AUTOSAR XML (schema 4-3-0)
package /Impl_SWC_HALIN_ARPkg
  swc implementation Impl_SWC_HALIN_type: programming-language=C, sw-version=1.0.0, vendor-id=0, behavior=SWC_HALIN_type_IB
    code-descriptors:
      code SRC: artifact-descriptors=autosar-engineering-object={short-label=EngObject, category=SWSRC}
    resource consumption ResourceConsumption
      memory section Mem_SWC_HALIN_CAL: size=0, sw-addrmethod=CAL, symbol=CAL
      memory section Mem_SWC_HALIN_CODE: size=0, sw-addrmethod=CODE, symbol=CODE
package /Impl_Type_HALIN_ARPkg
  8 x impl type:
    BHAL_CAN1_outputs: category=STRUCTURE
      134 x element, all with category=TYPE_REFERENCE:
        VHAL_CANMsgInvalidABM1_flg: implementation-data-type=boolean
        VHAL_ABM1CSErr_flg: implementation-data-type=boolean
        VHAL_ABM1RCErr_flg: implementation-data-type=boolean
        VHAL_ABMPassengerODSSta_flg: implementation-data-type=boolean
        VHAL_ABMRearPassengerCTRODSSta_flg: implementation-data-type=boolean
        VHAL_ABMRearPassengerLHODSSta_flg: implementation-data-type=boolean
        VHAL_ABMRearPassengerRHODSSta_flg: implementation-data-type=boolean
        VHAL_AirBagFailCmd_flg: implementation-data-type=boolean
        VHAL_ChecksumABM1_enum: implementation-data-type=uint8
        VHAL_CrashOutputSts_enum: implementation-data-type=uint8
        VHAL_DriverSeatBeltCmd_flg: implementation-data-type=boolean
        VHAL_LifeCountABM1_enum: implementation-data-type=uint8
        VHAL_PABSwitchCmd_flg: implementation-data-type=boolean
        VHAL_PsngrSeatBeltCmd_flg: implementation-data-type=boolean
        VHAL_RCenterSeatBeltCmd_flg: implementation-data-type=boolean
        VHAL_RDriverSeatBeltCmd_flg: implementation-data-type=boolean
        VHAL_RPsngrSeatBeltCmd_flg: implementation-data-type=boolean
        VHAL_TLHPsngrSeatBeltCmd_flg: implementation-data-type=boolean
        VHAL_TRHPsngrSeatBeltCmd_flg: implementation-data-type=boolean
        VHAL_CANMsgInvalidEPB1_flg: implementation-data-type=boolean
        VHAL_EPB1CSErr_flg: implementation-data-type=boolean
        VHAL_EPB1RCErr_flg: implementation-data-type=boolean
        VHAL_DOASta_flg: implementation-data-type=boolean
        VHAL_EPB1RC_enum: implementation-data-type=uint8
        VHAL_EPBCarWashMode_flg: implementation-data-type=boolean
        VHAL_EPBErrSta_enum: implementation-data-type=uint8
        VHAL_EPBExtApplyAvail_flg: implementation-data-type=boolean
        VHAL_EPBExtReleaseAvail_flg: implementation-data-type=boolean
        VHAL_EPBSta_enum: implementation-data-type=uint8
        VHAL_CANMsgInvalidEPS1_flg: implementation-data-type=boolean
        VHAL_EPS1CSErr_flg: implementation-data-type=boolean
        VHAL_EPS1RCErr_flg: implementation-data-type=boolean
        VHAL_DriIntend_enum: implementation-data-type=uint8
        VHAL_EPSAOIControl_enum: implementation-data-type=uint8
        VHAL_EPSRC_enum: implementation-data-type=uint8
        VHAL_EpasFailed_enum: implementation-data-type=uint8
        VHAL_SASAngle_Deg: implementation-data-type=float32
        VHAL_SASCAL_flg: implementation-data-type=boolean
        VHAL_SASSpeed_degps: implementation-data-type=float32
        VHAL_SASSpeedValid_flg: implementation-data-type=boolean
        VHAL_SASV_flg: implementation-data-type=boolean
        VHAL_CANMsgInvalidESC1_flg: implementation-data-type=boolean
        VHAL_ESC1CSErr_flg: implementation-data-type=boolean
        VHAL_ESC1RCErr_flg: implementation-data-type=boolean
        VHAL_ABSActive_flg: implementation-data-type=boolean
        VHAL_ABSFailed_flg: implementation-data-type=boolean
        VHAL_ABSWnlmpSta_flg: implementation-data-type=boolean
        VHAL_AVHActive_flg: implementation-data-type=boolean
        VHAL_AVHFailed_flg: implementation-data-type=boolean
        VHAL_AmberWnlmpSta_flg: implementation-data-type=boolean
        VHAL_BTCSActive_flg: implementation-data-type=boolean
        VHAL_EBDActive_flg: implementation-data-type=boolean
        VHAL_EBDFailed_flg: implementation-data-type=boolean
        VHAL_ESC1CS_enum: implementation-data-type=uint8
        VHAL_ESC1RC_enum: implementation-data-type=uint8
        VHAL_ESCActive_flg: implementation-data-type=boolean
        VHAL_ESCBeepReq_flg: implementation-data-type=boolean
        VHAL_ESCFailed_flg: implementation-data-type=boolean
        VHAL_ESCOFFStatus_enum: implementation-data-type=uint8
        VHAL_ESCOfflmpSta_flg: implementation-data-type=boolean
        VHAL_ESCWnlmpSta_enum: implementation-data-type=uint8
        VHAL_ESSActive_flg: implementation-data-type=boolean
        VHAL_FrPTCSActive_flg: implementation-data-type=boolean
        VHAL_FrntAxlTrqReqDrv_Nm: implementation-data-type=float32
        VHAL_GRADE_Deg: implementation-data-type=float32
        VHAL_HBBActive_flg: implementation-data-type=boolean
        VHAL_HBBFailed_flg: implementation-data-type=boolean
        VHAL_HDDActive_flg: implementation-data-type=boolean
        VHAL_HDDFailed_flg: implementation-data-type=boolean
        VHAL_HSAActive_flg: implementation-data-type=boolean
        VHAL_HSAFailed_flg: implementation-data-type=boolean
        VHAL_LFPulseCount_enum: implementation-data-type=uint8
        VHAL_LFPulseCountV_flg: implementation-data-type=boolean
        VHAL_LFRawWhlSpeed_kph: implementation-data-type=float32
        VHAL_LFRawWhlSpeedV_flg: implementation-data-type=boolean
        VHAL_LFWhlRotDir_enum: implementation-data-type=uint8
        VHAL_LRPulseCount_enum: implementation-data-type=uint8
        VHAL_LRPulseCountV_flg: implementation-data-type=boolean
        VHAL_LRRawWhlSpeed_kph: implementation-data-type=float32
        VHAL_LRRawWhlSpeedV_flg: implementation-data-type=boolean
        VHAL_LRWhlRotDir_enum: implementation-data-type=uint8
        VHAL_PBAActive_flg: implementation-data-type=boolean
        VHAL_PBAFailed_flg: implementation-data-type=boolean
        VHAL_RFPulseCount_enum: implementation-data-type=uint8
        VHAL_RFPulseCountV_flg: implementation-data-type=boolean
        VHAL_RFRawWhlSpeed_kph: implementation-data-type=float32
        VHAL_RFRawWhlSpeedV_flg: implementation-data-type=boolean
        VHAL_RFWhlRotDir_enum: implementation-data-type=uint8
        VHAL_RRPulseCount_enum: implementation-data-type=uint8
        VHAL_RRPulseCountV_flg: implementation-data-type=boolean
        VHAL_RRRawWhlSpeed_kph: implementation-data-type=float32
        VHAL_RRRawWhlSpeedV_flg: implementation-data-type=boolean
        VHAL_RRWhlRotDir_enum: implementation-data-type=uint8
        VHAL_RearAxlTrqReqDrv_Nm: implementation-data-type=float32
        VHAL_RedWnlmpSta_flg: implementation-data-type=boolean
        VHAL_RrPTCSActive_flg: implementation-data-type=boolean
        VHAL_TCSActive_flg: implementation-data-type=boolean
        VHAL_TCSFailed_flg: implementation-data-type=boolean
        VHAL_VehSpeed_kph: implementation-data-type=float32
        VHAL_CANMsgInvalidESC5_flg: implementation-data-type=boolean
        VHAL_ESC5CSErr_flg: implementation-data-type=boolean
        VHAL_ESC5RCErr_flg: implementation-data-type=boolean
        VHAL_ACCAvail_flg: implementation-data-type=boolean
        VHAL_AEBAvail_flg: implementation-data-type=boolean
        VHAL_ActBrkLampSta_flg: implementation-data-type=boolean
        VHAL_BrkDiscTempSta_flg: implementation-data-type=boolean
        VHAL_BrkPedalPos_pct: implementation-data-type=float32
        VHAL_BrkPedalPosSta_flg: implementation-data-type=boolean
        VHAL_BrkSwSta_flg: implementation-data-type=boolean
        VHAL_BrkSwV_flg: implementation-data-type=boolean
        VHAL_ESC5CS_enum: implementation-data-type=uint8
        VHAL_ESC5RC_enum: implementation-data-type=uint8
        VHAL_ESCADASSta_enum: implementation-data-type=uint8
        VHAL_ESCAPSSta_enum: implementation-data-type=uint8
        VHAL_ESCStandstill_flg: implementation-data-type=boolean
        VHAL_FrRBCActive_flg: implementation-data-type=boolean
        VHAL_FrntAxlTrqReqBrk_Nm: implementation-data-type=float32
        VHAL_LatAccel_Gps: implementation-data-type=float32
        VHAL_LatAccelV_flg: implementation-data-type=boolean
        VHAL_LongAccel_Gps: implementation-data-type=float32
        VHAL_LongAccelV_flg: implementation-data-type=boolean
        VHAL_MCPressure_bar: implementation-data-type=float32
        VHAL_MCPressureV_flg: implementation-data-type=boolean
        VHAL_MeterIndVehSpeed_kph: implementation-data-type=float32
        VHAL_RDCActive_enum: implementation-data-type=uint8
        VHAL_RearAxlTrqReqBrk_Nm: implementation-data-type=float32
        VHAL_RrRBCActive_flg: implementation-data-type=boolean
        VHAL_YawRate_degps: implementation-data-type=float32
        VHAL_YawRateV_flg: implementation-data-type=boolean
        VHAL_CANMsgInvalideBST1_flg: implementation-data-type=boolean
        VHAL_LowBrakeFluidSta_flg: implementation-data-type=boolean
        VHAL_eBSTAmberWnlmpSta_flg: implementation-data-type=boolean
        VHAL_eBSTBeepReq_flg: implementation-data-type=boolean
        VHAL_eBSTRedWnlmpSta_flg: implementation-data-type=boolean
    BHAL_CAN2_outputs: category=STRUCTURE
      196 x element, all with category=TYPE_REFERENCE:
        VHAL_CANMsgInvalidHMI1_flg: implementation-data-type=boolean
        VHAL_HMIACAirIntMCmd_flg: implementation-data-type=boolean
        VHAL_HMIACAirIntPCmd_flg: implementation-data-type=boolean
        VHAL_HMIACAutoBtnCmd_flg: implementation-data-type=boolean
        VHAL_HMIACBtnCmd_flg: implementation-data-type=boolean
        VHAL_HMIACFrDefogBtnCmd_flg: implementation-data-type=boolean
        VHAL_HMIACRecycleBtnCmd_flg: implementation-data-type=boolean
        VHAL_HMIACWindDirMCmd_flg: implementation-data-type=boolean
        VHAL_HMIACWindDirPCmd_flg: implementation-data-type=boolean
        VHAL_HMIAutoInterLightCmd_flg: implementation-data-type=boolean
        VHAL_HMIBCMPostDefogBtnCmd_flg: implementation-data-type=boolean
        VHAL_HMIZLSetTMCmd_flg: implementation-data-type=boolean
        VHAL_HMIZLSetTPCmd_flg: implementation-data-type=boolean
        VHAL_HMIZRSetTMCmd_flg: implementation-data-type=boolean
        VHAL_HMIZRSetTPCmd_flg: implementation-data-type=boolean
        VHAL_CANMsgInvalidIVI1_flg: implementation-data-type=boolean
        VHAL_AmbLighLowBatAlertSW_flg: implementation-data-type=boolean
        VHAL_AmbLighSafetyAlertSW_flg: implementation-data-type=boolean
        VHAL_AmbLightBrightnessSet_enum: implementation-data-type=uint8
        VHAL_AmbLightColorSet_enum: implementation-data-type=uint8
        VHAL_AmbLightDimInDarkSW_flg: implementation-data-type=boolean
        VHAL_AmbLightSW_flg: implementation-data-type=boolean
        VHAL_AmbLightWlcmLightSW_flg: implementation-data-type=boolean
        VHAL_FCPFrEvtBtnACMaxReq_flg: implementation-data-type=boolean
        VHAL_FCPFrEvtBtnACReq_flg: implementation-data-type=boolean
        VHAL_FCPFrEvtBtnAutoReq_flg: implementation-data-type=boolean
        VHAL_FCPFrEvtBtnSyncReq_flg: implementation-data-type=boolean
        VHAL_IVIAutoWipHSpdSWCmd_flg: implementation-data-type=boolean
        VHAL_IVICLWinLockDoorSWSta_flg: implementation-data-type=boolean
        VHAL_IVICreateAccReqSta_enum: implementation-data-type=uint8
        VHAL_IVIDelAccReqSta_enum: implementation-data-type=uint8
        VHAL_IVIDrivingLockSWSta_flg: implementation-data-type=boolean
        VHAL_IVIEPSForceCmd_enum: implementation-data-type=uint8
        VHAL_IVIFrTrunkUnlockReqSta_flg: implementation-data-type=boolean
        VHAL_IVILinkAccReqSta_flg: implementation-data-type=boolean
        VHAL_IVILinkAccSta_enum: implementation-data-type=uint8
        VHAL_IVILinkKeySta_enum: implementation-data-type=uint8
        VHAL_IVILocatedSTA_enum: implementation-data-type=uint8
        VHAL_IVILockSoundSWSta_flg: implementation-data-type=boolean
        VHAL_IVIMirrorFoldedSWSta_flg: implementation-data-type=boolean
        VHAL_IVISWCVibModeSta_enum: implementation-data-type=uint8
        VHAL_IVISilentChrgAlertSta_flg: implementation-data-type=boolean
        VHAL_IVIStoppingUnlockSWSta_flg: implementation-data-type=boolean
        VHAL_IVITimeCheck_enum: implementation-data-type=uint8
        VHAL_IVITimeDay_DAY: implementation-data-type=float32
        VHAL_IVITimeHour_hr: implementation-data-type=float32
        VHAL_IVITimeMinute_min: implementation-data-type=float32
        VHAL_IVITimeMonth_MONTH: implementation-data-type=float32
        VHAL_IVITimeSecond_s: implementation-data-type=float32
        VHAL_IVITimeYear_YEAR: implementation-data-type=float32
        VHAL_IVIWPTCSWSta_flg: implementation-data-type=boolean
        VHAL_IVIsigScreenReqSta_flg: implementation-data-type=boolean
        VHAL_LINKtoDrive_flg: implementation-data-type=boolean
        VHAL_OpenDrOpenWdoSW_flg: implementation-data-type=boolean
        VHAL_PWCONTINUEUSE_flg: implementation-data-type=boolean
        VHAL_SmartEcoModeSW_flg: implementation-data-type=boolean
        VHAL_UserSet_enum: implementation-data-type=uint8
        VHAL_CANMsgInvalidIVI2_flg: implementation-data-type=boolean
        VHAL_ACChgCurSet_A: implementation-data-type=float32
        VHAL_AVMErrSTA_flg: implementation-data-type=boolean
        VHAL_AVMOFFRecButt_flg: implementation-data-type=boolean
        VHAL_AVMParkingmode_enum: implementation-data-type=uint8
        VHAL_AVMparkingcancel_enum: implementation-data-type=uint8
        VHAL_AVMparkingexcute_enum: implementation-data-type=uint8
        VHAL_ApproachUnlockSW_flg: implementation-data-type=boolean
        VHAL_CAASSw_enum: implementation-data-type=uint8
        VHAL_CDLLockButt_flg: implementation-data-type=boolean
        VHAL_CDLUnlockButt_flg: implementation-data-type=boolean
        VHAL_DSEATantiset_flg: implementation-data-type=boolean
        VHAL_DSEATentryfunset_flg: implementation-data-type=boolean
        VHAL_DSEATventreq_enum: implementation-data-type=uint8
        VHAL_Distanceunit_flg: implementation-data-type=boolean
        VHAL_ESCSWCmd_enum: implementation-data-type=uint8
        VHAL_FSOffSw_enum: implementation-data-type=uint8
        VHAL_FollowMeSW_flg: implementation-data-type=boolean
        VHAL_GPSLAT_s: implementation-data-type=float32
        VHAL_GPSLONG_enum: implementation-data-type=uint32
        VHAL_HeadLampSW_enum: implementation-data-type=uint8
        VHAL_HoodLatchSW_enum: implementation-data-type=uint8
        VHAL_IVIACCAdaptiveSta_flg: implementation-data-type=boolean
        VHAL_IVIAirIntZ3Cmd_enum: implementation-data-type=uint8
        VHAL_IVICarWashModeCmd_flg: implementation-data-type=boolean
        VHAL_IVIChargePortSWSta_flg: implementation-data-type=boolean
        VHAL_IVICreepSWReq_flg: implementation-data-type=boolean
        VHAL_IVIDSEATHeaterCmd_enum: implementation-data-type=uint8
        VHAL_IVIDSEATFroEdgeHeightCmd_enum: implementation-data-type=uint8
        VHAL_IVIDSEATHeightCmd_enum: implementation-data-type=uint8
        VHAL_IVIDSEATMemory1Sta_flg: implementation-data-type=boolean
        VHAL_IVIDSEATMemory2Sta_flg: implementation-data-type=boolean
        VHAL_IVIDSEATMemoryOPTCLSSta_flg: implementation-data-type=boolean
        VHAL_IVIDSEATReclineCmd_enum: implementation-data-type=uint8
        VHAL_IVIDSEATSlideCmd_enum: implementation-data-type=uint8
        VHAL_IVIFGSAirIntCmd_enum: implementation-data-type=uint8
        VHAL_IVIFGSChCmd_enum: implementation-data-type=uint8
        VHAL_IVIIONSWCmd_flg: implementation-data-type=boolean
        VHAL_IVIISAOffsetSpd_enum: implementation-data-type=uint8
        VHAL_IVINightModeSta_flg: implementation-data-type=boolean
        VHAL_IVIPSEATHeaterCmd_enum: implementation-data-type=uint8
        VHAL_IVIPSEATReclineCmd_enum: implementation-data-type=uint8
        VHAL_IVIPSEATSlideCmd_enum: implementation-data-type=uint8
        VHAL_IVIPTGModeSW_enum: implementation-data-type=uint8
        VHAL_IVIPTGOpenHeight_enum: implementation-data-type=uint8
        VHAL_IVIPTGStaSW_enum: implementation-data-type=uint8
        VHAL_IVIPTGUSStaSW_flg: implementation-data-type=boolean
        VHAL_IVIPWModeReq_enum: implementation-data-type=uint8
        VHAL_IVIPwrLockSW_enum: implementation-data-type=uint8
        VHAL_IVIPwroffreq_flg: implementation-data-type=boolean
        VHAL_IVIRRDefReq_flg: implementation-data-type=boolean
        VHAL_IVIReqV2L_enum: implementation-data-type=uint8
        VHAL_IVISWCRUndefinedSta_enum: implementation-data-type=uint8
        VHAL_IVIScreen_enum: implementation-data-type=uint8
        VHAL_IVIStartChgreq_flg: implementation-data-type=boolean
        VHAL_IVIStatus_flg: implementation-data-type=boolean
        VHAL_IVIStopChgreq_flg: implementation-data-type=boolean
        VHAL_IVITrailerCheckReqSta_flg: implementation-data-type=boolean
        VHAL_IVITrailerModeSWSta_flg: implementation-data-type=boolean
        VHAL_IVITriggerreq_flg: implementation-data-type=boolean
        VHAL_IVIUnlockChgreq_flg: implementation-data-type=boolean
        VHAL_IVIWIMAINSW_flg: implementation-data-type=boolean
        VHAL_LDrvControlCommand_pct: implementation-data-type=float32
        VHAL_LPasControlCommand_pct: implementation-data-type=float32
        VHAL_LRLDControlCommand_pct: implementation-data-type=float32
        VHAL_LRRDControlCommand_pct: implementation-data-type=float32
        VHAL_LightShowStartReq_flg: implementation-data-type=boolean
        VHAL_LightShowStopReq_flg: implementation-data-type=boolean
        VHAL_MFRDNBrightReq_pct: implementation-data-type=float32
        VHAL_OFFACMODE_enum: implementation-data-type=uint8
        VHAL_PSEATventreq_enum: implementation-data-type=uint8
        VHAL_PerdV2L_enum: implementation-data-type=uint8
        VHAL_RFogLampSW_flg: implementation-data-type=boolean
        VHAL_RollModeSWCmd_enum: implementation-data-type=uint8
        VHAL_RoomLampMode_flg: implementation-data-type=boolean
        VHAL_SOCADJBUTT_flg: implementation-data-type=boolean
        VHAL_SOCLimitSet_pct: implementation-data-type=float32
        VHAL_SOCV2LLimit_pct: implementation-data-type=float32
        VHAL_SchedChgStart_flg: implementation-data-type=boolean
        VHAL_SchedChgStop_flg: implementation-data-type=boolean
        VHAL_SchedChgbutt_flg: implementation-data-type=boolean
        VHAL_SchedChglimit_pct: implementation-data-type=float32
        VHAL_SchedChgwake_flg: implementation-data-type=boolean
        VHAL_SenstivityPosition_enum: implementation-data-type=uint8
        VHAL_SetUnlockSingle_flg: implementation-data-type=boolean
        VHAL_TCSSWCmd_enum: implementation-data-type=uint8
        VHAL_TPMSCaliButt_flg: implementation-data-type=boolean
        VHAL_TPMSResButt_flg: implementation-data-type=boolean
        VHAL_TurnSwTimeSet_enum: implementation-data-type=uint8
        VHAL_WalkawayLockSW_flg: implementation-data-type=boolean
        VHAL_WlcmLightMode_enum: implementation-data-type=uint8
        VHAL_sigAirIntenZon1Req_enum: implementation-data-type=uint8
        VHAL_sigDfrstReq_flg: implementation-data-type=boolean
        VHAL_sigFaceReq_flg: implementation-data-type=boolean
        VHAL_sigFootReq_flg: implementation-data-type=boolean
        VHAL_sigRecircReq_flg: implementation-data-type=boolean
        VHAL_sigSetTempZon1Req_C: implementation-data-type=float32
        VHAL_sigSetTempZon2Req_C: implementation-data-type=float32
        VHAL_CANMsgInvalidIVI3_flg: implementation-data-type=boolean
        VHAL_IVICLBlowerYSta_pct: implementation-data-type=float32
        VHAL_IVICLBlowerZSta_pct: implementation-data-type=float32
        VHAL_IVICRBlowerYSta_pct: implementation-data-type=float32
        VHAL_IVICRBlowerZSta_pct: implementation-data-type=float32
        VHAL_IVIHMICustmiFunSta_enum: implementation-data-type=uint8
        VHAL_IVIHMICustmiKEYSta_enum: implementation-data-type=uint8
        VHAL_IVILBlowerModeSta_enum: implementation-data-type=uint8
        VHAL_IVILBlowerYSta_pct: implementation-data-type=float32
        VHAL_IVILBlowerZSta_pct: implementation-data-type=float32
        VHAL_IVILSEATventCmd_enum: implementation-data-type=uint8
        VHAL_IVIMLFMostCmd_flg: implementation-data-type=boolean
        VHAL_IVIMLFootLiftCmd_enum: implementation-data-type=uint8
        VHAL_IVIMLNapModeCmd_flg: implementation-data-type=boolean
        VHAL_IVIMLReclinerCmd_enum: implementation-data-type=uint8
        VHAL_IVIMLRestoreCmd_flg: implementation-data-type=boolean
        VHAL_IVIMLSEATventCmd_enum: implementation-data-type=uint8
        VHAL_IVIMLSeatLiftCmd_enum: implementation-data-type=uint8
        VHAL_IVIMLSldRestoreCmd_flg: implementation-data-type=boolean
        VHAL_IVIMLSliderCmd_enum: implementation-data-type=uint8
        VHAL_IVIMLZeroGravityCmd_flg: implementation-data-type=boolean
        VHAL_IVIMRFMostCmd_flg: implementation-data-type=boolean
        VHAL_IVIMRFootLiftCmd_enum: implementation-data-type=uint8
        VHAL_IVIMRNapModeCmd_flg: implementation-data-type=boolean
        VHAL_IVIMRReclinerCmd_enum: implementation-data-type=uint8
        VHAL_IVIMRRestoreCmd_flg: implementation-data-type=boolean
        VHAL_IVIMRSEATventCmd_enum: implementation-data-type=uint8
        VHAL_IVIMRSeatLiftCmd_enum: implementation-data-type=uint8
        VHAL_IVIMRSldRestoreCmd_flg: implementation-data-type=boolean
        VHAL_IVIMRSliderCmd_enum: implementation-data-type=uint8
        VHAL_IVIMRZeroGravityCmd_flg: implementation-data-type=boolean
        VHAL_IVIRBlowerModeSta_enum: implementation-data-type=uint8
        VHAL_IVIRBlowerYSta_pct: implementation-data-type=float32
        VHAL_IVIRBlowerZSta_pct: implementation-data-type=float32
        VHAL_IVIRSEATventCmd_enum: implementation-data-type=uint8
        VHAL_IVISnowModeCmd_flg: implementation-data-type=boolean
        VHAL_IVIUserTakeOverAPSSta_flg: implementation-data-type=boolean
        VHAL_IVIZon1WindDirSWReqSta_flg: implementation-data-type=boolean
        VHAL_CANMsgInvalidMETER1_flg: implementation-data-type=boolean
        VHAL_METERKPHCalcu_kph: implementation-data-type=float32
        VHAL_ODOMETER_km: implementation-data-type=float32
    BHAL_CAN3_outputs: category=STRUCTURE
      298 x element, all with category=TYPE_REFERENCE:
        VHAL_CANMsgInvalidBMS1_flg: implementation-data-type=boolean
        VHAL_BMS1CSErr_flg: implementation-data-type=boolean
        VHAL_BMS1RCErr_flg: implementation-data-type=boolean
        VHAL_BMSChckSum1_enum: implementation-data-type=uint8
        VHAL_BMSRolCnct1_enum: implementation-data-type=uint8
        VHAL_HVBPwrAvailChrg_kW: implementation-data-type=float32
        VHAL_HVBPwrAvailChrg30_kW: implementation-data-type=float32
        VHAL_HVBPwrAvailChrg60_kW: implementation-data-type=float32
        VHAL_HVBPwrAvailDchrg_kW: implementation-data-type=float32
        VHAL_HVBPwrAvailDchrg30_kW: implementation-data-type=float32
        VHAL_HVBPwrAvailDchrg60_kW: implementation-data-type=float32
        VHAL_HVBattCurr_A: implementation-data-type=float32
        VHAL_HVBattVolt_V: implementation-data-type=float32
        VHAL_CANMsgInvalidBMS3_flg: implementation-data-type=boolean
        VHAL_ACChrgCurrDis_A: implementation-data-type=float32
        VHAL_FireDetErr_flg: implementation-data-type=boolean
        VHAL_HVBChrgPwr_kWh: implementation-data-type=float32
        VHAL_HVBChrgPwrTotal_kWh: implementation-data-type=float32
        VHAL_HVBDrvPwr_kWh: implementation-data-type=float32
        VHAL_HVBDrvPwrTotal_kWh: implementation-data-type=float32
        VHAL_HVBFullChrgPwr_kWh: implementation-data-type=float32
        VHAL_HVBIsoImpedenceN_Megaohm: implementation-data-type=float32
        VHAL_HVBIsoImpedenceP_Megaohm: implementation-data-type=float32
        VHAL_HVBSOH_pct: implementation-data-type=float32
        VHAL_HVBattErr_flg: implementation-data-type=boolean
        VHAL_HVBattPackVolt_V: implementation-data-type=float32
        VHAL_HVBattSOC_pct: implementation-data-type=float32
        VHAL_HVBattSOCDis_pct: implementation-data-type=float32
        VHAL_RemainChrgTime_min: implementation-data-type=float32
        VHAL_CANMsgInvalidBMS4_flg: implementation-data-type=boolean
        VHAL_CellTempAvg_C: implementation-data-type=float32
        VHAL_HVBCellVoltMax_mV: implementation-data-type=float32
        VHAL_HVBCellVoltMin_mV: implementation-data-type=float32
        VHAL_HVBMTempMax_C: implementation-data-type=float32
        VHAL_HVBMTempMin_C: implementation-data-type=float32
        VHAL_MaxCellTempNum_enum: implementation-data-type=uint8
        VHAL_MaxCellVoltNum_enum: implementation-data-type=uint8
        VHAL_MinCellTempNum_enum: implementation-data-type=uint8
        VHAL_MinCellVoltNum_enum: implementation-data-type=uint8
        VHAL_CANMsgInvalidBMS5_flg: implementation-data-type=boolean
        VHAL_HVInVolt_V: implementation-data-type=float32
        VHAL_LVBattDet12V_V: implementation-data-type=float32
        VHAL_OBCACCSLimit_A: implementation-data-type=float32
        VHAL_OBCDCCurLm_A: implementation-data-type=float32
        VHAL_OBCDCVoltLm_V: implementation-data-type=float32
        VHAL_CANMsgInvalidBMS6_flg: implementation-data-type=boolean
        VHAL_BMS6CSErr_flg: implementation-data-type=boolean
        VHAL_BMS6RCErr_flg: implementation-data-type=boolean
        VHAL_BMSChckSum_enum: implementation-data-type=uint8
        VHAL_BMSRolCnct_enum: implementation-data-type=uint8
        VHAL_BMSREADY_flg: implementation-data-type=boolean
        VHAL_BMSWarn{1..8}_flg: implementation-data-type=boolean
        VHAL_ChrgInLockReq_enum: implementation-data-type=uint8
        VHAL_ChrgPlugSta_enum: implementation-data-type=uint8
        VHAL_DisChrgPlugErr_enum: implementation-data-type=uint8
        VHAL_ExtChrgSta_enum: implementation-data-type=uint8
        VHAL_HVBChrgErr_enum: implementation-data-type=uint8
        VHAL_HVBContactorSta_flg: implementation-data-type=boolean
        VHAL_HVBHVILErr_flg: implementation-data-type=boolean
        VHAL_HVBOvrTempErr_flg: implementation-data-type=boolean
        VHAL_HVBOvrTempWarn_enum: implementation-data-type=uint8
        VHAL_HVBPreheatPrecoolSta_enum: implementation-data-type=uint8
        VHAL_HVBattReady4Pre_enum: implementation-data-type=uint8
        VHAL_HVILSta_flg: implementation-data-type=boolean
        VHAL_V2LSta_enum: implementation-data-type=uint8
        VHAL_CANMsgInvalidBMS8_flg: implementation-data-type=boolean
        VHAL_MainRlyNegSta_enum: implementation-data-type=uint8
        VHAL_MainRlyPosSta_enum: implementation-data-type=uint8
        VHAL_CANMsgInvalidCCU1_flg: implementation-data-type=boolean
        VHAL_CCU1CSErr_flg: implementation-data-type=boolean
        VHAL_CCU1RCErr_flg: implementation-data-type=boolean
        VHAL_CSCCU1_enum: implementation-data-type=uint8
        VHAL_DCDCAuxCur_A: implementation-data-type=float32
        VHAL_DCDCAuxVolt_V: implementation-data-type=float32
        VHAL_DCDCHVCur_A: implementation-data-type=float32
        VHAL_DCDCInVoltInf_V: implementation-data-type=float32
        VHAL_DCDCPreCompleted_enum: implementation-data-type=uint8
        VHAL_OBCDCCurrInf_A: implementation-data-type=float32
        VHAL_OBCDCVoltInf_V: implementation-data-type=float32
        VHAL_OBCPreCompleted_enum: implementation-data-type=uint8
        VHAL_OBCWakeup4Plugin_flg: implementation-data-type=boolean
        VHAL_RCCCU1_enum: implementation-data-type=uint8
        VHAL_CANMsgInvalidCCU2_flg: implementation-data-type=boolean
        VHAL_CCU2CSErr_flg: implementation-data-type=boolean
        VHAL_CCU2RCErr_flg: implementation-data-type=boolean
        VHAL_CSCCU2_enum: implementation-data-type=uint8
        VHAL_DCDCEnaSta_flg: implementation-data-type=boolean
        VHAL_DCDCFaultSta_enum: implementation-data-type=uint8
        VHAL_DCDCReady4Pre_flg: implementation-data-type=boolean
        VHAL_DCDCTemp_C: implementation-data-type=float32
        VHAL_OBCACCurrInf_A: implementation-data-type=float32
        VHAL_OBCACVoltInf_V: implementation-data-type=float32
        VHAL_OBCEnaSta_flg: implementation-data-type=boolean
        VHAL_OBCFaultSta_enum: implementation-data-type=uint8
        VHAL_OBCPluginSta_flg: implementation-data-type=boolean
        VHAL_OBCReady4Pre_flg: implementation-data-type=boolean
        VHAL_OBCTemp_C: implementation-data-type=float32
        VHAL_OBCV2LSta_enum: implementation-data-type=uint8
        VHAL_OBCACCurLim_enum: implementation-data-type=uint8
        VHAL_RCCCU2_enum: implementation-data-type=uint8
        VHAL_CANMsgInvalidEBM1_flg: implementation-data-type=boolean
        VHAL_EBMErrSta_enum: implementation-data-type=uint8
        VHAL_EBMRLampSta_enum: implementation-data-type=uint8
        VHAL_CANMsgInvalidMCUBF1_flg: implementation-data-type=boolean
        VHAL_MCUBF1CSErr_flg: implementation-data-type=boolean
        VHAL_MCUBF1RCErr_flg: implementation-data-type=boolean
        VHAL_FrActvDmpDisabSta_flg: implementation-data-type=boolean
        VHAL_FrEDUDrtSta_flg: implementation-data-type=boolean
        VHAL_FrEDUOpratingSta_flg: implementation-data-type=boolean
        VHAL_FrEDURealTMTq_Nm: implementation-data-type=float32
        VHAL_FrEDURotateDirction_enum: implementation-data-type=uint8
        VHAL_FrEDUTqReqFbk_Nm: implementation-data-type=float32
        VHAL_FrMCU1Chksum_enum: implementation-data-type=uint8
        VHAL_FrMCU1RolCnt_enum: implementation-data-type=uint8
        VHAL_FrMCUBAT_V: implementation-data-type=float32
        VHAL_FrMCUDCBusCurr_A: implementation-data-type=float32
        VHAL_FrMCUDCBusVolt_V: implementation-data-type=float32
        VHAL_FrMCUDischrgSta_flg: implementation-data-type=boolean
        VHAL_FrMCUEnaSta_flg: implementation-data-type=boolean
        VHAL_FrMCUErr_enum: implementation-data-type=uint8
        VHAL_FrMCUIGNsta_flg: implementation-data-type=boolean
        VHAL_FrMCUReady_flg: implementation-data-type=boolean
        VHAL_FrMCUReady4Pre_flg: implementation-data-type=boolean
        VHAL_FrMCUSysSta_enum: implementation-data-type=uint8
        VHAL_FrMCUTemp_C: implementation-data-type=float32
        VHAL_FrMotorAvailTq_Nm: implementation-data-type=float32
        VHAL_FrRegenAvailTq_Nm: implementation-data-type=float32
        VHAL_FrTMSpd_rpm: implementation-data-type=float32
        VHAL_FrTMTemp_C: implementation-data-type=float32
        VHAL_FrTMid_A: implementation-data-type=float32
        VHAL_FrTMiq_A: implementation-data-type=float32
        VHAL_MCUWarnF_enum: implementation-data-type=uint8
        VHAL_MCUBFRealPwrKwSta_kW: implementation-data-type=float32
        VHAL_CANMsgInvalidMCUBF2_flg: implementation-data-type=boolean
        VHAL_FrCoolanttempReq_C: implementation-data-type=float32
        VHAL_FrFailcode1_enum: implementation-data-type=uint8
        VHAL_FrFailcode2_enum: implementation-data-type=uint8
        VHAL_FrFailcodehistory1_enum: implementation-data-type=uint8
        VHAL_FrFailcodehistory2_enum: implementation-data-type=uint8
        VHAL_FrLLCTemp_C: implementation-data-type=float32
        VHAL_FrLLCflowReq_Lpmin: implementation-data-type=float32
        VHAL_FrMCUTempWarn_enum: implementation-data-type=uint8
        VHAL_FrMCUHWVer_enum: implementation-data-type=uint16
        VHAL_FrMCUSWVer_enum: implementation-data-type=uint16
        VHAL_FrTMTempWarn_enum: implementation-data-type=uint8
        VHAL_MCUBFLLCTempWarnSta_enum: implementation-data-type=uint8
        VHAL_CANMsgInvalidMCUBR1_flg: implementation-data-type=boolean
        VHAL_MCUBR1CSErr_flg: implementation-data-type=boolean
        VHAL_MCUBR1RCErr_flg: implementation-data-type=boolean
        VHAL_MCUWarnR_enum: implementation-data-type=uint8
        VHAL_MCUBRRealPwrKwSta_kW: implementation-data-type=float32
        VHAL_RrActvDmpDisabSta_flg: implementation-data-type=boolean
        VHAL_RrEDUDrtSta_flg: implementation-data-type=boolean
        VHAL_RrEDUOpratingSta_flg: implementation-data-type=boolean
        VHAL_RrEDURealTMTq_Nm: implementation-data-type=float32
        VHAL_RrEDURotateDirction_enum: implementation-data-type=uint8
        VHAL_RrEDUTqReqFbk_Nm: implementation-data-type=float32
        VHAL_RrMCU1Chksum_enum: implementation-data-type=uint8
        VHAL_RrMCU1RolCnt_enum: implementation-data-type=uint8
        VHAL_RrMCUBAT_V: implementation-data-type=float32
        VHAL_RrMCUDCBusCurr_A: implementation-data-type=float32
        VHAL_RrMCUDCBusVolt_V: implementation-data-type=float32
        VHAL_RrMCUDischrgSta_flg: implementation-data-type=boolean
        VHAL_RrMCUEnaSta_flg: implementation-data-type=boolean
        VHAL_RrMCUErr_enum: implementation-data-type=uint8
        VHAL_RrMCUIGNsta_flg: implementation-data-type=boolean
        VHAL_RrMCUReady_flg: implementation-data-type=boolean
        VHAL_RrMCUReady4Pre_flg: implementation-data-type=boolean
        VHAL_RrMCUSysSta_enum: implementation-data-type=uint8
        VHAL_RrMCUTemp_C: implementation-data-type=float32
        VHAL_RrMotorAvailTq_Nm: implementation-data-type=float32
        VHAL_RrRegenAvailTq_Nm: implementation-data-type=float32
        VHAL_RrTMSpd_rpm: implementation-data-type=float32
        VHAL_RrTMTemp_C: implementation-data-type=float32
        VHAL_RrTMid_A: implementation-data-type=float32
        VHAL_RrTMiq_A: implementation-data-type=float32
        VHAL_CANMsgInvalidMCUBR2_flg: implementation-data-type=boolean
        VHAL_MCUBRLLCTempWarnSta_enum: implementation-data-type=uint8
        VHAL_RrCoolanttempReq_cnt: implementation-data-type=float32
        VHAL_RrFailcode1_enum: implementation-data-type=uint8
        VHAL_RrFailcode2_enum: implementation-data-type=uint8
        VHAL_RrFailcodehistory1_enum: implementation-data-type=uint8
        VHAL_RrFailcodehistory2_enum: implementation-data-type=uint8
        VHAL_RrLLCTemp_C: implementation-data-type=float32
        VHAL_RrLLCflowReq_Lpmin: implementation-data-type=float32
        VHAL_RrMCU3HWVer_enum: implementation-data-type=uint16
        VHAL_RrMCU3SWVer_enum: implementation-data-type=uint16
        VHAL_RrMCUTempWarn_enum: implementation-data-type=uint8
        VHAL_RrTMTempWarn_enum: implementation-data-type=uint8
        VHAL_CANMsgInvalidMCUNF1_flg: implementation-data-type=boolean
        VHAL_MCUNF1CSErr_flg: implementation-data-type=boolean
        VHAL_MCUNF1RCErr_flg: implementation-data-type=boolean
        VHAL_FrActvDmpDisabStaNidec_flg: implementation-data-type=boolean
        VHAL_FrEDUDrtStaNidec_flg: implementation-data-type=boolean
        VHAL_FrEDUOpratingStaNidec_flg: implementation-data-type=boolean
        VHAL_FrEDURealTMTqNidec_Nm: implementation-data-type=float32
        VHAL_FrEDURotateDirctionNidec_enum: implementation-data-type=uint8
        VHAL_FrEDUTqReqFbkNidec_Nm: implementation-data-type=float32
        VHAL_FrMCU1ChksumNidec_enum: implementation-data-type=uint8
        VHAL_FrMCU1RolCntNidec_enum: implementation-data-type=uint8
        VHAL_FrMCUBATNidec_V: implementation-data-type=float32
        VHAL_FrMCUDCBusCurrNidec_A: implementation-data-type=float32
        VHAL_FrMCUDCBusVoltNidec_V: implementation-data-type=float32
        VHAL_FrMCUDischrgStaNidec_flg: implementation-data-type=boolean
        VHAL_FrMCUEnaStaNidec_flg: implementation-data-type=boolean
        VHAL_FrMCUErrNidec_enum: implementation-data-type=uint8
        VHAL_FrMCUIGNstaNidec_flg: implementation-data-type=boolean
        VHAL_FrMCUReady4PreNidec_flg: implementation-data-type=boolean
        VHAL_FrMCUReadyNidec_flg: implementation-data-type=boolean
        VHAL_FrMCUSysStaNidec_enum: implementation-data-type=uint8
        VHAL_FrMCUTempNidec_C: implementation-data-type=float32
        VHAL_FrMotorAvailTqNidec_Nm: implementation-data-type=float32
        VHAL_FrRegenAvailTqNidec_Nm: implementation-data-type=float32
        VHAL_FrTMSpdNidec_rpm: implementation-data-type=float32
        VHAL_FrTMTempNidec_C: implementation-data-type=float32
        VHAL_FrTMidNidec_A: implementation-data-type=float32
        VHAL_FrTMiqNidec_A: implementation-data-type=float32
        VHAL_MCUWarnFNidec_enum: implementation-data-type=uint8
        VHAL_CANMsgInvalidMCUNF2_flg: implementation-data-type=boolean
        VHAL_FrCoolanttempReqNidec_C: implementation-data-type=float32
        VHAL_FrEOPSpdSetNidec_rpm: implementation-data-type=float32
        VHAL_FrFailcode1Nidec_enum: implementation-data-type=uint8
        VHAL_FrFailcode2Nidec_enum: implementation-data-type=uint8
        VHAL_FrFailcodehistory1Nidec_enum: implementation-data-type=uint8
        VHAL_FrFailcodehistory2Nidec_enum: implementation-data-type=uint8
        VHAL_FrLLCTempNidec_C: implementation-data-type=float32
        VHAL_FrLLCflowReqNidec_Lpmin: implementation-data-type=float32
        VHAL_FrMCUTempWarnNidec_enum: implementation-data-type=uint8
        VHAL_FrTMTempWarnNidec_enum: implementation-data-type=uint8
        VHAL_CANMsgInvalidMCUNF3_flg: implementation-data-type=boolean
        VHAL_FrMCUHWVerNidec_enum: implementation-data-type=uint16
        VHAL_FrMCUSWVerNidec_enum: implementation-data-type=uint16
        VHAL_CANMsgInvalidMCUNR1_flg: implementation-data-type=boolean
        VHAL_MCUNR1CSErr_flg: implementation-data-type=boolean
        VHAL_MCUNR1RCErr_flg: implementation-data-type=boolean
        VHAL_MCUWarnRNidec_enum: implementation-data-type=uint8
        VHAL_RrActvDmpDisabStaNidec_flg: implementation-data-type=boolean
        VHAL_RrEDUDrtStaNidec_flg: implementation-data-type=boolean
        VHAL_RrEDUOpratingStaNidec_flg: implementation-data-type=boolean
        VHAL_RrEDURealTMTqNidec_Nm: implementation-data-type=float32
        VHAL_RrEDURotateDirctionNidec_enum: implementation-data-type=uint8
        VHAL_RrEDUTqReqFbkNidec_Nm: implementation-data-type=float32
        VHAL_RrMCU1ChksumNidec_enum: implementation-data-type=uint8
        VHAL_RrMCU1RolCntNidec_enum: implementation-data-type=uint8
        VHAL_RrMCUBATNidec_V: implementation-data-type=float32
        VHAL_RrMCUDCBusCurrNidec_A: implementation-data-type=float32
        VHAL_RrMCUDCBusVoltNidec_V: implementation-data-type=float32
        VHAL_RrMCUDischrgStaNidec_flg: implementation-data-type=boolean
        VHAL_RrMCUEnaStaNidec_flg: implementation-data-type=boolean
        VHAL_RrMCUErrNidec_enum: implementation-data-type=uint8
        VHAL_RrMCUIGNstaNidec_flg: implementation-data-type=boolean
        VHAL_RrMCUReady4PreNidec_flg: implementation-data-type=boolean
        VHAL_RrMCUReadyNidec_flg: implementation-data-type=boolean
        VHAL_RrMCUSysStaNidec_enum: implementation-data-type=uint8
        VHAL_RrMCUTempNidec_C: implementation-data-type=float32
        VHAL_RrMotorAvailTqNidec_Nm: implementation-data-type=float32
        VHAL_RrRegenAvailTqNidec_Nm: implementation-data-type=float32
        VHAL_RrTMSpdNidec_rpm: implementation-data-type=float32
        VHAL_RrTMTempNidec_C: implementation-data-type=float32
        VHAL_RrTMidNidec_A: implementation-data-type=float32
        VHAL_RrTMiqNidec_A: implementation-data-type=float32
        VHAL_CANMsgInvalidMCUNR2_flg: implementation-data-type=boolean
        VHAL_RrCoolanttempReqNidec_cnt: implementation-data-type=float32
        VHAL_RrEOPSpdSetNidec_rpm: implementation-data-type=float32
        VHAL_RrFailcode1Nidec_enum: implementation-data-type=uint8
        VHAL_RrFailcode2Nidec_enum: implementation-data-type=uint8
        VHAL_RrFailcodehistory1Nidec_enum: implementation-data-type=uint8
        VHAL_RrFailcodehistory2Nidec_enum: implementation-data-type=uint8
        VHAL_RrLLCTempNidec_C: implementation-data-type=float32
        VHAL_RrLLCflowReqNidec_Lpmin: implementation-data-type=float32
        VHAL_RrMCUTempWarnNidec_enum: implementation-data-type=uint8
        VHAL_RrTMTempWarnNidec_enum: implementation-data-type=uint8
        VHAL_CANMsgInvalidMCUNR3_flg: implementation-data-type=boolean
        VHAL_RrMCU3HWVerNidec_enum: implementation-data-type=uint16
        VHAL_RrMCU3SWVerNidec_enum: implementation-data-type=uint16
        VHAL_CANMsgInvalidShifter1_flg: implementation-data-type=boolean
        VHAL_Shifter1CSErr_flg: implementation-data-type=boolean
        VHAL_Shifter1RCErr_flg: implementation-data-type=boolean
        VHAL_ShifterCRC8_enum: implementation-data-type=uint8
        VHAL_ShifterFailsta_enum: implementation-data-type=uint8
        VHAL_ShifterHandleCmd_enum: implementation-data-type=uint8
        VHAL_ShifterRC_enum: implementation-data-type=uint8
        VHAL_CANMsgInvalidShifter2_flg: implementation-data-type=boolean
        VHAL_Shifter2CSErr_flg: implementation-data-type=boolean
        VHAL_Shifter2RCErr_flg: implementation-data-type=boolean
        VHAL_CSW2DimSwSta_flg: implementation-data-type=boolean
        VHAL_CSW2FWasSwSta_enum: implementation-data-type=uint8
        VHAL_CSW2FWipSwSta_enum: implementation-data-type=uint8
        VHAL_CSW2PassSWSta_flg: implementation-data-type=boolean
        VHAL_CSW2RWipWasSwSta_enum: implementation-data-type=uint8
        VHAL_CSW2TurnSwSta_enum: implementation-data-type=uint8
    BHAL_CAN4_outputs: category=STRUCTURE
      272 x element, all with category=TYPE_REFERENCE:
        VHAL_CANMsgInvalidBodyZoneDR1_flg: implementation-data-type=boolean
        VHAL_BDDSEATAntiSta_flg: implementation-data-type=boolean
        VHAL_BDDSEATEntryFunSta_flg: implementation-data-type=boolean
        VHAL_BDDSEATErrorSta_flg: implementation-data-type=boolean
        VHAL_BDDSEATMemSetSta_enum: implementation-data-type=uint8
        VHAL_BDDSEATModeSta_enum: implementation-data-type=uint8
        VHAL_BDDSEATVentSta_enum: implementation-data-type=uint8
        VHAL_BDDSEATheaterSta_enum: implementation-data-type=uint8
        VHAL_CANMsgInvalidBodyZoneDR2_flg: implementation-data-type=boolean
        VHAL_BDAPMWinFOpenedSta_pct: implementation-data-type=float32
        VHAL_BDAPMWinROpenedSta_pct: implementation-data-type=float32
        VHAL_BDDoorFHandleCloseSta_flg: implementation-data-type=boolean
        VHAL_BDDoorRHandleCloseSta_flg: implementation-data-type=boolean
        VHAL_CANMsgInvalidBodyZonePS1_flg: implementation-data-type=boolean
        VHAL_BPPSEATErrorSta_flg: implementation-data-type=boolean
        VHAL_BPPSEATModeSta_enum: implementation-data-type=uint8
        VHAL_BPPSEATVentSta_enum: implementation-data-type=uint8
        VHAL_BPPSEATheaterSta_enum: implementation-data-type=uint8
        VHAL_BPPTGActiveSta_enum: implementation-data-type=uint8
        VHAL_BPPTGExistSta_flg: implementation-data-type=boolean
        VHAL_BPPTGInsideSW1Sta_enum: implementation-data-type=uint8
        VHAL_BPPTGInsideSW2Sta_enum: implementation-data-type=uint8
        VHAL_BPPTGIsSetHeightSta_flg: implementation-data-type=boolean
        VHAL_BPPTGLeftHallPosnSta_enum: implementation-data-type=uint16
        VHAL_BPPTGOpenRatioSta_pct: implementation-data-type=float32
        VHAL_BPPTGRDILCmd_enum: implementation-data-type=uint8
        VHAL_BPPTGSysSta_enum: implementation-data-type=uint8
        VHAL_CANMsgInvalidBodyZonePS2_flg: implementation-data-type=boolean
        VHAL_BPAPMWinFOpenedSta_pct: implementation-data-type=float32
        VHAL_BPAPMWinROpenedSta_pct: implementation-data-type=float32
        VHAL_BPDoorFHandleCloseSta_flg: implementation-data-type=boolean
        VHAL_BPDoorRHandleCloseSta_flg: implementation-data-type=boolean
        VHAL_BPSEATLVentSta_enum: implementation-data-type=uint8
        VHAL_BPSEATMLVentSta_enum: implementation-data-type=uint8
        VHAL_BPSEATMRVentSta_enum: implementation-data-type=uint8
        VHAL_BPSEATRVentSta_enum: implementation-data-type=uint8
        VHAL_CANMsgInvalidDKC1_flg: implementation-data-type=boolean
        VHAL_DKCKeyNumSta_enum: implementation-data-type=uint8
        VHAL_DKCKeyTypeSta_enum: implementation-data-type=uint8
        VHAL_DKCPDkeyAreaRAPSSta_enum: implementation-data-type=uint8
        VHAL_DKCParkingModeCmd_enum: implementation-data-type=uint8
        VHAL_DKCReVehData_enum: implementation-data-type=uint8
        VHAL_PCommandToBCM_enum: implementation-data-type=uint8
        VHAL_PCommandToPTG_enum: implementation-data-type=uint8
        VHAL_PDKeyAreaLockUnlock_enum: implementation-data-type=uint8
        VHAL_PDKeyAreaPS_enum: implementation-data-type=uint8
        VHAL_PDKeyAreaPTG_enum: implementation-data-type=uint8
        VHAL_PDKeyWelcome_enum: implementation-data-type=uint8
        VHAL_PDkeyShowIVI_enum: implementation-data-type=uint8
        VHAL_PKeyMiss_flg: implementation-data-type=boolean
        VHAL_PKeyMode_enum: implementation-data-type=uint8
        VHAL_PUIDLowPower_flg: implementation-data-type=boolean
        VHAL_CANMsgInvalidDKC2_flg: implementation-data-type=boolean
        VHAL_EncryptionDATA063_enum: implementation-data-type=uint64
        VHAL_EncryptionDATA64127_enum: implementation-data-type=uint64
        VHAL_RandomNumberX_enum: implementation-data-type=uint64
        VHAL_CANMsgInvalidPTG1_flg: implementation-data-type=boolean
        VHAL_PTGActiveSta_enum: implementation-data-type=uint8
        VHAL_PTGAutoStaus_flg: implementation-data-type=boolean
        VHAL_PTGExist_flg: implementation-data-type=boolean
        VHAL_PTGHWVer_enum: implementation-data-type=uint8
        VHAL_PTGInnerSW2_enum: implementation-data-type=uint8
        VHAL_PTGIsSetHeight_flg: implementation-data-type=boolean
        VHAL_PTGOpenRatio_pct: implementation-data-type=float32
        VHAL_PTGRDILSta_enum: implementation-data-type=uint8
        VHAL_PTGSWVer_enum: implementation-data-type=uint8
        VHAL_PTGSysSta_enum: implementation-data-type=uint8
        VHAL_CANMsgInvalidZONEDR1_flg: implementation-data-type=boolean
        VHAL_DrLockSta_flg: implementation-data-type=boolean
        VHAL_MIRRORFOLDSW_flg: implementation-data-type=boolean
        VHAL_RLTurnLPErr_flg: implementation-data-type=boolean
        VHAL_RLTurnLampC_mA: implementation-data-type=float32
        VHAL_RRTurnLPErr_flg: implementation-data-type=boolean
        VHAL_RRTurnLampC_mA: implementation-data-type=float32
        VHAL_RWiperAS_flg: implementation-data-type=boolean
        VHAL_RWiperProtection_flg: implementation-data-type=boolean
        VHAL_CANMsgInvalidZONEDRVCU_flg: implementation-data-type=boolean
        VHAL_BlowerErr_enum: implementation-data-type=uint8
        VHAL_DrPMMLVOutPErrLmp_flg: implementation-data-type=boolean
        VHAL_DrPMMSysErrLmp_flg: implementation-data-type=boolean
        VHAL_DrSCPSysErrLmp_flg: implementation-data-type=boolean
        VHAL_DrStdAErrSta_flg: implementation-data-type=boolean
        VHAL_LeftHallPos_enum: implementation-data-type=uint16
        VHAL_SolarL_W: implementation-data-type=float32
        VHAL_SolarLErr_enum: implementation-data-type=uint8
        VHAL_SolarR_W: implementation-data-type=float32
        VHAL_SolarRErr_enum: implementation-data-type=uint8
        VHAL_TFaceL_C: implementation-data-type=float32
        VHAL_TFaceLErr_enum: implementation-data-type=uint8
        VHAL_TFaceR_C: implementation-data-type=float32
        VHAL_TFaceRErr_enum: implementation-data-type=uint8
        VHAL_TFaceRr_C: implementation-data-type=float32
        VHAL_TFaceRrErr_enum: implementation-data-type=uint8
        VHAL_TFootL_C: implementation-data-type=float32
        VHAL_TFootLErr_enum: implementation-data-type=uint8
        VHAL_TFootR_C: implementation-data-type=float32
        VHAL_TFootRErr_enum: implementation-data-type=uint8
        VHAL_TFootRr_C: implementation-data-type=float32
        VHAL_TFootRrErr_enum: implementation-data-type=uint8
        VHAL_Tevap_C: implementation-data-type=float32
        VHAL_TevapErr_enum: implementation-data-type=uint8
        VHAL_Tincar_C: implementation-data-type=float32
        VHAL_TincarErr_enum: implementation-data-type=uint8
        VHAL_ZoneDrMalfunLevel_enum: implementation-data-type=uint8
        VHAL_CANMsgInvalidZONEFR1_flg: implementation-data-type=boolean
        VHAL_ChargeInletLockSta_flg: implementation-data-type=boolean
        VHAL_CompProEN_flg: implementation-data-type=boolean
        VHAL_FLTurnLPErr_flg: implementation-data-type=boolean
        VHAL_FLTurnLampC_mA: implementation-data-type=float32
        VHAL_FLTurnLightWarning_flg: implementation-data-type=boolean
        VHAL_FRTurnLPErr_flg: implementation-data-type=boolean
        VHAL_FRTurnLampC_mA: implementation-data-type=float32
        VHAL_FRTurnLightWarning_flg: implementation-data-type=boolean
        VHAL_FWiperAS_flg: implementation-data-type=boolean
        VHAL_FWiperProtection_flg: implementation-data-type=boolean
        VHAL_LADBHibeamIndication_flg: implementation-data-type=boolean
        VHAL_LADBOperationStatus_flg: implementation-data-type=boolean
        VHAL_LADBWarning_flg: implementation-data-type=boolean
        VHAL_LAHBWarning_flg: implementation-data-type=boolean
        VHAL_LDRLWarning_flg: implementation-data-type=boolean
        VHAL_LLBWarning_flg: implementation-data-type=boolean
        VHAL_LpositionLampWarning_flg: implementation-data-type=boolean
        VHAL_RADBHibeamIndication_flg: implementation-data-type=boolean
        VHAL_RADBOperationStatus_flg: implementation-data-type=boolean
        VHAL_RADBWarning_flg: implementation-data-type=boolean
        VHAL_RAHBWarning_flg: implementation-data-type=boolean
        VHAL_RDRLWarning_flg: implementation-data-type=boolean
        VHAL_RLBWarning_flg: implementation-data-type=boolean
        VHAL_RpositionLampWarning_flg: implementation-data-type=boolean
        VHAL_TrailerCheck_flg: implementation-data-type=boolean
        VHAL_TrailerModeSta_enum: implementation-data-type=uint8
        VHAL_ZFRBCMChargerDoorSWSta_flg: implementation-data-type=boolean
        VHAL_ZFRBCMHRLTurnLPNormalSta_flg: implementation-data-type=boolean
        VHAL_ZFRBCMHRRTurnLPHNormalSta_flg: implementation-data-type=boolean
        VHAL_ZFRTHCMCLEVentActYSta_pct: implementation-data-type=float32
        VHAL_ZFRTHCMCREVentActYSta_pct: implementation-data-type=float32
        VHAL_ZFRTHCMLEVentActYSta_pct: implementation-data-type=float32
        VHAL_ZFRTHCMREVentActYSta_pct: implementation-data-type=float32
        VHAL_CANMsgInvalidZONEFRVCU_flg: implementation-data-type=boolean
        VHAL_AGSErr_enum: implementation-data-type=uint8
        VHAL_BatInTemp_C: implementation-data-type=float32
        VHAL_BatInTempErr_enum: implementation-data-type=uint8
        VHAL_BatOutTemp_C: implementation-data-type=float32
        VHAL_COMPErr_enum: implementation-data-type=uint8
        VHAL_EACProtectEnable_enum: implementation-data-type=uint8
        VHAL_EWP3Err_enum: implementation-data-type=uint8
        VHAL_EXV1Err_enum: implementation-data-type=uint8
        VHAL_EXV2Err_enum: implementation-data-type=uint8
        VHAL_FanErr_enum: implementation-data-type=uint8
        VHAL_FrPMMLimpHomeActReq_flg: implementation-data-type=boolean
        VHAL_MotorInTemp_C: implementation-data-type=float32
        VHAL_MotorInTempErr_enum: implementation-data-type=uint8
        VHAL_MotorOutTemp_C: implementation-data-type=float32
        VHAL_MotorOutTempErr_enum: implementation-data-type=uint8
        VHAL_PTHighP_KPa: implementation-data-type=float32
        VHAL_PTHighPErr_enum: implementation-data-type=uint8
        VHAL_PTHighTact_C: implementation-data-type=float32
        VHAL_PTHighTactErr_enum: implementation-data-type=uint8
        VHAL_PTLowP1_KPa: implementation-data-type=float32
        VHAL_PTLowP1Err_enum: implementation-data-type=uint8
        VHAL_PTLowP2_KPa: implementation-data-type=float32
        VHAL_PTLowP2Err_enum: implementation-data-type=uint8
        VHAL_PTLowT1_C: implementation-data-type=float32
        VHAL_PTLowT1Err_enum: implementation-data-type=uint8
        VHAL_PTLowT2_C: implementation-data-type=float32
        VHAL_PTLowT2Err_enum: implementation-data-type=uint8
        VHAL_SOTXVErr_enum: implementation-data-type=uint8
        VHAL_SOV{1..3}Err_enum: implementation-data-type=uint8
        VHAL_Tamb_C: implementation-data-type=float32
        VHAL_TambErr_enum: implementation-data-type=uint8
        VHAL_CANMsgInvalidzGWAPTC1_flg: implementation-data-type=boolean
        VHAL_FrntPTCLeActHeatPwr_W: implementation-data-type=float32
        VHAL_FrntPTCRearLeActHeatPwr_W: implementation-data-type=float32
        VHAL_FrntPTCRearRiActHeatPwr_W: implementation-data-type=float32
        VHAL_FrntPTCRiActHeatPwr_W: implementation-data-type=float32
        VHAL_CANMsgInvalidzGWCANFr1_flg: implementation-data-type=boolean
        VHAL_COMPActualPwr_W: implementation-data-type=float32
        VHAL_COMPConCur_A: implementation-data-type=float32
        VHAL_COMPConVolt_V: implementation-data-type=float32
        VHAL_COMPStatorSpd_rpm: implementation-data-type=float32
        VHAL_PTC1PowerConsumption_kW: implementation-data-type=float32
        VHAL_CANMsgInvalidzGWLINDr1_flg: implementation-data-type=boolean
        VHAL_CSWDimSw_flg: implementation-data-type=boolean
        VHAL_CSWFWasSwSta_enum: implementation-data-type=uint8
        VHAL_CSWFWipSwSta_enum: implementation-data-type=uint8
        VHAL_CSWPassSWSta_flg: implementation-data-type=boolean
        VHAL_CSWRWasSWSta_enum: implementation-data-type=uint8
        VHAL_CSWRWipIntSwSta_enum: implementation-data-type=uint8
        VHAL_CSWTurnSwSta_enum: implementation-data-type=uint8
        VHAL_FAPWL01LINResponseError_flg: implementation-data-type=boolean
        VHAL_LDrvMotorRelayError_flg: implementation-data-type=boolean
        VHAL_LDrvMotorRippleError_flg: implementation-data-type=boolean
        VHAL_LDrvValWdwOpened_pct: implementation-data-type=float32
        VHAL_LDrvWdwPositionSts_enum: implementation-data-type=uint8
        VHAL_LPasMotorRelayError_flg: implementation-data-type=boolean
        VHAL_LPasMotorRippleError_flg: implementation-data-type=boolean
        VHAL_LPasValWdwOpened_pct: implementation-data-type=float32
        VHAL_LPasWdwPositionSts_enum: implementation-data-type=uint8
        VHAL_LRLDMotorRelayError_flg: implementation-data-type=boolean
        VHAL_LRLDMotorRippleError_flg: implementation-data-type=boolean
        VHAL_LRLDValWdwOpened_pct: implementation-data-type=float32
        VHAL_LRLDWdwPositionSts_enum: implementation-data-type=uint8
        VHAL_LRRDMotorRelayError_flg: implementation-data-type=boolean
        VHAL_LRRDMotorRippleError_flg: implementation-data-type=boolean
        VHAL_LRRDValWdwOpened_pct: implementation-data-type=float32
        VHAL_LRRDWdwPositionSts_enum: implementation-data-type=uint8
        VHAL_RAPWL01LINResponseError_flg: implementation-data-type=boolean
        VHAL_RLSLampSta_flg: implementation-data-type=boolean
        VHAL_RLSRainSnrWiperCmd_enum: implementation-data-type=uint8
        VHAL_SWC2LADASSta_flg: implementation-data-type=boolean
        VHAL_SWC2LDriveModeSta_flg: implementation-data-type=boolean
        VHAL_SWC2LHomeSta_flg: implementation-data-type=boolean
        VHAL_SWC2LLeftSta_flg: implementation-data-type=boolean
        VHAL_SWC2LRegenUpSta_flg: implementation-data-type=boolean
        VHAL_SWC2LRightSta_flg: implementation-data-type=boolean
        VHAL_SWC2LScrollDownSta_flg: implementation-data-type=boolean
        VHAL_SWC2LScrollPressSta_flg: implementation-data-type=boolean
        VHAL_SWC2LScrollUpSta_flg: implementation-data-type=boolean
        VHAL_SWC2RCustomizeSta_flg: implementation-data-type=boolean
        VHAL_SWC2RLeftSta_flg: implementation-data-type=boolean
        VHAL_SWC2RPageSwitchSta_flg: implementation-data-type=boolean
        VHAL_SWC2RRegenDownSta_flg: implementation-data-type=boolean
        VHAL_SWC2RRightSta_flg: implementation-data-type=boolean
        VHAL_SWC2RScrollDownSta_flg: implementation-data-type=boolean
        VHAL_SWC2RScrollPressSta_flg: implementation-data-type=boolean
        VHAL_SWC2RScrollUpSta_flg: implementation-data-type=boolean
        VHAL_SWC2RVRSta_flg: implementation-data-type=boolean
        VHAL_SWCACCSta_flg: implementation-data-type=boolean
        VHAL_SWCCANCELSta_flg: implementation-data-type=boolean
        VHAL_SWCDistanceSta_flg: implementation-data-type=boolean
        VHAL_SWCDownSta_flg: implementation-data-type=boolean
        VHAL_SWCLKASta_flg: implementation-data-type=boolean
        VHAL_SWCLeftSta_flg: implementation-data-type=boolean
        VHAL_SWCRegenDown_flg: implementation-data-type=boolean
        VHAL_SWCRegenUp_flg: implementation-data-type=boolean
        VHAL_SWCResUpSta_flg: implementation-data-type=boolean
        VHAL_SWCRightSta_flg: implementation-data-type=boolean
        VHAL_SWCSetdownSta_flg: implementation-data-type=boolean
        VHAL_SWCTripSta_flg: implementation-data-type=boolean
        VHAL_SWCUndefinedSta_flg: implementation-data-type=boolean
        VHAL_SWCUpSta_flg: implementation-data-type=boolean
        VHAL_SWCVRSta_flg: implementation-data-type=boolean
        VHAL_SWCmodeSta_flg: implementation-data-type=boolean
        VHAL_CANMsgInvalidzGWLINDr2_flg: implementation-data-type=boolean
        VHAL_ACT1ResponseError_flg: implementation-data-type=boolean
        VHAL_CANMsgInvalidzGWLINFr1_flg: implementation-data-type=boolean
        VHAL_AGSActualPosition_enum: implementation-data-type=uint8
        VHAL_FGSIntenRspSta_enum: implementation-data-type=uint8
        VHAL_CANMsgInvalidzGWLINFr2_flg: implementation-data-type=boolean
        VHAL_EWP1BlockError_enum: implementation-data-type=uint8
        VHAL_EWP1OverCurrError_enum: implementation-data-type=uint8
        VHAL_EWP2BlockError_enum: implementation-data-type=uint8
        VHAL_EWP2OverCurrError_enum: implementation-data-type=uint8
        VHAL_EWP3BlockError_enum: implementation-data-type=uint8
        VHAL_EWP3OverCurrError_enum: implementation-data-type=uint8
        VHAL_CANMsgInvalidzGWSEAT1_flg: implementation-data-type=boolean
        VHAL_DSEATAntiSta_flg: implementation-data-type=boolean
        VHAL_DSEATEntryFunSta_flg: implementation-data-type=boolean
        VHAL_DSEATErrorSta_flg: implementation-data-type=boolean
        VHAL_DSEATHWVer_enum: implementation-data-type=uint16
        VHAL_DSEATMode_enum: implementation-data-type=uint8
        VHAL_DSEATSWVer_enum: implementation-data-type=uint16
        VHAL_DSEATVentSta_enum: implementation-data-type=uint8
        VHAL_DSEATheatersta_enum: implementation-data-type=uint8
        VHAL_PSEATErrorSta_flg: implementation-data-type=boolean
        VHAL_PSEATHWVer_enum: implementation-data-type=uint16
        VHAL_PSEATMode_enum: implementation-data-type=uint8
        VHAL_PSEATSWVer_enum: implementation-data-type=uint16
        VHAL_PSEATVentSta_enum: implementation-data-type=uint8
        VHAL_PSEATheatersta_enum: implementation-data-type=uint8
    BHAL_CAN5_outputs: category=STRUCTURE
      21 x element, all with category=TYPE_REFERENCE:
        VHAL_CANMsgInvalidTBOX2_flg: implementation-data-type=boolean
        VHAL_TimeSyncFromBSDay_DAY: implementation-data-type=float32
        VHAL_TimeSyncFromBSHour_hr: implementation-data-type=float32
        VHAL_TimeSyncFromBSMinute_min: implementation-data-type=float32
        VHAL_TimeSyncFromBSMonth_MONTH: implementation-data-type=float32
        VHAL_TimeSyncFromBSSecond_s: implementation-data-type=float32
        VHAL_TimeSyncFromBSYear_YEAR: implementation-data-type=float32
        VHAL_CANMsgInvalidTBOX3_flg: implementation-data-type=boolean
        VHAL_ChargePercentSet_pct: implementation-data-type=float32
        VHAL_ReserveChargeOFFDay_DAY: implementation-data-type=float32
        VHAL_ReserveChargeOFFHour_hr: implementation-data-type=float32
        VHAL_ReserveChargeOFFMinute_min: implementation-data-type=float32
        VHAL_ReserveChargeOFFMonth_MONTH: implementation-data-type=float32
        VHAL_ReserveChargeOFFYear_YEAR: implementation-data-type=float32
        VHAL_ReserveChargeOnDay_DAY: implementation-data-type=float32
        VHAL_ReserveChargeOnHour_hr: implementation-data-type=float32
        VHAL_ReserveChargeOnMinute_min: implementation-data-type=float32
        VHAL_ReserveChargeOnMonth_MONTH: implementation-data-type=float32
        VHAL_ReserveChargeOnYear_YEAR: implementation-data-type=float32
        VHAL_TBOXHWVER_enum: implementation-data-type=uint32
        VHAL_TBOXSWVER_enum: implementation-data-type=uint32
    BHAL_CAN6_outputs: category=STRUCTURE
      99 x element, all with category=TYPE_REFERENCE:
        VHAL_CANMsgInvalidFCM1_flg: implementation-data-type=boolean
        VHAL_ACCComfortBandLower_mps2: implementation-data-type=float32
        VHAL_ACCComfortBandUpper_mps2: implementation-data-type=float32
        VHAL_ACCJerkLowerLimit_mps3: implementation-data-type=float32
        VHAL_ACCJerkUpperLimit_mps3: implementation-data-type=float32
        VHAL_ACCObjDist_m: implementation-data-type=float32
        VHAL_ACCObjDstLvl_enum: implementation-data-type=uint8
        VHAL_ACCObjRelSpd_mps: implementation-data-type=float32
        VHAL_ACCRequiredAccel_mps2: implementation-data-type=float32
        VHAL_ACCTakeoverReq_flg: implementation-data-type=boolean
        VHAL_ACCVehHoldReq_flg: implementation-data-type=boolean
        VHAL_ADASACCSta_enum: implementation-data-type=uint8
        VHAL_ADASAEBReq_enum: implementation-data-type=uint8
        VHAL_ADASAEBSta_enum: implementation-data-type=uint8
        VHAL_ADASCAMSpdLim_enum: implementation-data-type=uint8
        VHAL_ADASDBSReq_enum: implementation-data-type=uint8
        VHAL_ADASFCWMute_flg: implementation-data-type=boolean
        VHAL_ADASFCWSta_enum: implementation-data-type=uint8
        VHAL_ADASFaultSta_flg: implementation-data-type=boolean
        VHAL_ADASFltWrnReq_flg: implementation-data-type=boolean
        VHAL_ADASForceIdle_flg: implementation-data-type=boolean
        VHAL_ADASISASta_enum: implementation-data-type=uint8
        VHAL_ADASLDWMute_flg: implementation-data-type=boolean
        VHAL_ADASLDWSta_enum: implementation-data-type=uint8
        VHAL_ADASLFCHandsOffWarning_enum: implementation-data-type=uint8
        VHAL_ADASLFCSta_enum: implementation-data-type=uint8
        VHAL_ADASLFCWarnSound_enum: implementation-data-type=uint8
        VHAL_ADASLKASta_enum: implementation-data-type=uint8
        VHAL_ADASLaneModeL_enum: implementation-data-type=uint8
        VHAL_ADASLaneModeR_enum: implementation-data-type=uint8
        VHAL_ADASLanecurveL_raw32: implementation-data-type=float32
        VHAL_ADASLanecurveR_raw32: implementation-data-type=float32
        VHAL_ADASLanetypeL_enum: implementation-data-type=uint8
        VHAL_ADASLanetypeR_enum: implementation-data-type=uint8
        VHAL_ADASSLIFSpdLim_enum: implementation-data-type=uint8
        VHAL_ADASSLIFSta_enum: implementation-data-type=uint8
        VHAL_ADASShftPosnReq_enum: implementation-data-type=uint8
        VHAL_ADASShftPosnReqA_flg: implementation-data-type=boolean
        VHAL_ADASVehSpdLim_enum: implementation-data-type=uint8
        VHAL_ADASWarningMsg_enum: implementation-data-type=uint8
        VHAL_AEBVehHoldReq_flg: implementation-data-type=boolean
        VHAL_CameraBlockage_flg: implementation-data-type=boolean
        VHAL_FCM1Checksum_enum: implementation-data-type=uint8
        VHAL_FCM1LifeCount_enum: implementation-data-type=uint8
        VHAL_FCMACCmode_enum: implementation-data-type=uint8
        VHAL_FCMLKAStrToqReq_Nm: implementation-data-type=float32
        VHAL_FCMLKATOIAct_enum: implementation-data-type=uint8
        VHAL_FCMLKATOIFault_flg: implementation-data-type=boolean
        VHAL_ForceLowBeam_enum: implementation-data-type=uint8
        VHAL_HazardWarningReq_flg: implementation-data-type=boolean
        VHAL_ISAWarningMsg_enum: implementation-data-type=uint8
        VHAL_LKAHODDisplayWarning_flg: implementation-data-type=boolean
        VHAL_LKAHODSoundWarning_flg: implementation-data-type=boolean
        VHAL_LVDAACCStatusInformation_flg: implementation-data-type=boolean
        VHAL_LVDADisabled_flg: implementation-data-type=boolean
        VHAL_LVDAFailinfo_flg: implementation-data-type=boolean
        VHAL_LVDAMuteSta_enum: implementation-data-type=uint8
        VHAL_LVDAWarning_flg: implementation-data-type=boolean
        VHAL_LeftTurnLightReq_flg: implementation-data-type=boolean
        VHAL_RightTurnLightReq_flg: implementation-data-type=boolean
        VHAL_TargetType_enum: implementation-data-type=uint8
        VHAL_TimeGapLevel_enum: implementation-data-type=uint8
        VHAL_CANMsgInvalidFCM2_flg: implementation-data-type=boolean
        VHAL_FCM2CSErr_flg: implementation-data-type=boolean
        VHAL_FCM2RCErr_flg: implementation-data-type=boolean
        VHAL_ADBVehDst1Val_enum: implementation-data-type=uint8
        VHAL_CANMsgInvalidFCM3_flg: implementation-data-type=boolean
        VHAL_MELaneCurvDervLt_raw32: implementation-data-type=float32
        VHAL_MELaneCurvDervLt2_raw32: implementation-data-type=float32
        VHAL_MELaneCurvDervRt_raw32: implementation-data-type=float32
        VHAL_MELaneCurvDervRt2_raw32: implementation-data-type=float32
        VHAL_MELaneCurvLt_raw32: implementation-data-type=float32
        VHAL_MELaneCurvLt2_raw32: implementation-data-type=float32
        VHAL_MELaneCurvRt_raw32: implementation-data-type=float32
        VHAL_MELaneCurvRt2_raw32: implementation-data-type=float32
        VHAL_MELaneHeadAngLt_radians: implementation-data-type=float32
        VHAL_MELaneHeadAngLt2_radians: implementation-data-type=float32
        VHAL_MELaneHeadAngRt_radians: implementation-data-type=float32
        VHAL_MELaneHeadAngRt2_radians: implementation-data-type=float32
        VHAL_MELanePosLt_m: implementation-data-type=float32
        VHAL_MELanePosLt2_m: implementation-data-type=float32
        VHAL_MELanePosRt_m: implementation-data-type=float32
        VHAL_MELanePosRt2_m: implementation-data-type=float32
        VHAL_CANMsgInvalidFCM4_flg: implementation-data-type=boolean
        VHAL_FCM4CSErr_flg: implementation-data-type=boolean
        VHAL_FCM4RCErr_flg: implementation-data-type=boolean
        VHAL_ADASAngCtrlTqWeightGain_pct: implementation-data-type=float32
        VHAL_ADASDesStrWhlAngCtrlCmd_Deg: implementation-data-type=float32
        VHAL_ADASDrvInputTqBoostAct_flg: implementation-data-type=boolean
        VHAL_ADASDrvInputTqBoostGain_pct: implementation-data-type=float32
        VHAL_ADASMaxAngCtrlOutTqLimit_Nm: implementation-data-type=float32
        VHAL_ADASStrWhlAngCtrlStatus_flg: implementation-data-type=boolean
        VHAL_CANMsgInvalidSRR1_flg: implementation-data-type=boolean
        VHAL_SRRBSDWarnL_enum: implementation-data-type=uint8
        VHAL_SRRBSDWarnR_enum: implementation-data-type=uint8
        VHAL_SRRODASoundL_flg: implementation-data-type=boolean
        VHAL_SRRODASoundR_flg: implementation-data-type=boolean
        VHAL_SRRODAWarnL_enum: implementation-data-type=uint8
        VHAL_SRRODAWarnR_enum: implementation-data-type=uint8
    u8_Array16_type: category=ARRAY
      element u8_Array16: category=VALUE, array-size=16, array-size-semantics=FIXED-SIZE, base-type=uint8
    u8_Array8_type: category=ARRAY
      element u8_Array8: category=VALUE, array-size=8, array-size-semantics=FIXED-SIZE, base-type=uint8
package /Interface_HALIN_ARPkg
  6 x sender receiver interface:
    IF_BHAL_CAN1_outputs
      data BHAL_CAN1_outputs: type=BHAL_CAN1_outputs
    IF_BHAL_CAN2_outputs
      data BHAL_CAN2_outputs: type=BHAL_CAN2_outputs
    IF_BHAL_CAN3_outputs
      data BHAL_CAN3_outputs: type=BHAL_CAN3_outputs
    IF_BHAL_CAN4_outputs
      data BHAL_CAN4_outputs: type=BHAL_CAN4_outputs
    IF_BHAL_CAN5_outputs
      data BHAL_CAN5_outputs: type=BHAL_CAN5_outputs
    IF_BHAL_CAN6_outputs
      data BHAL_CAN6_outputs: type=BHAL_CAN6_outputs
package /SWC_HALIN_ARPkg
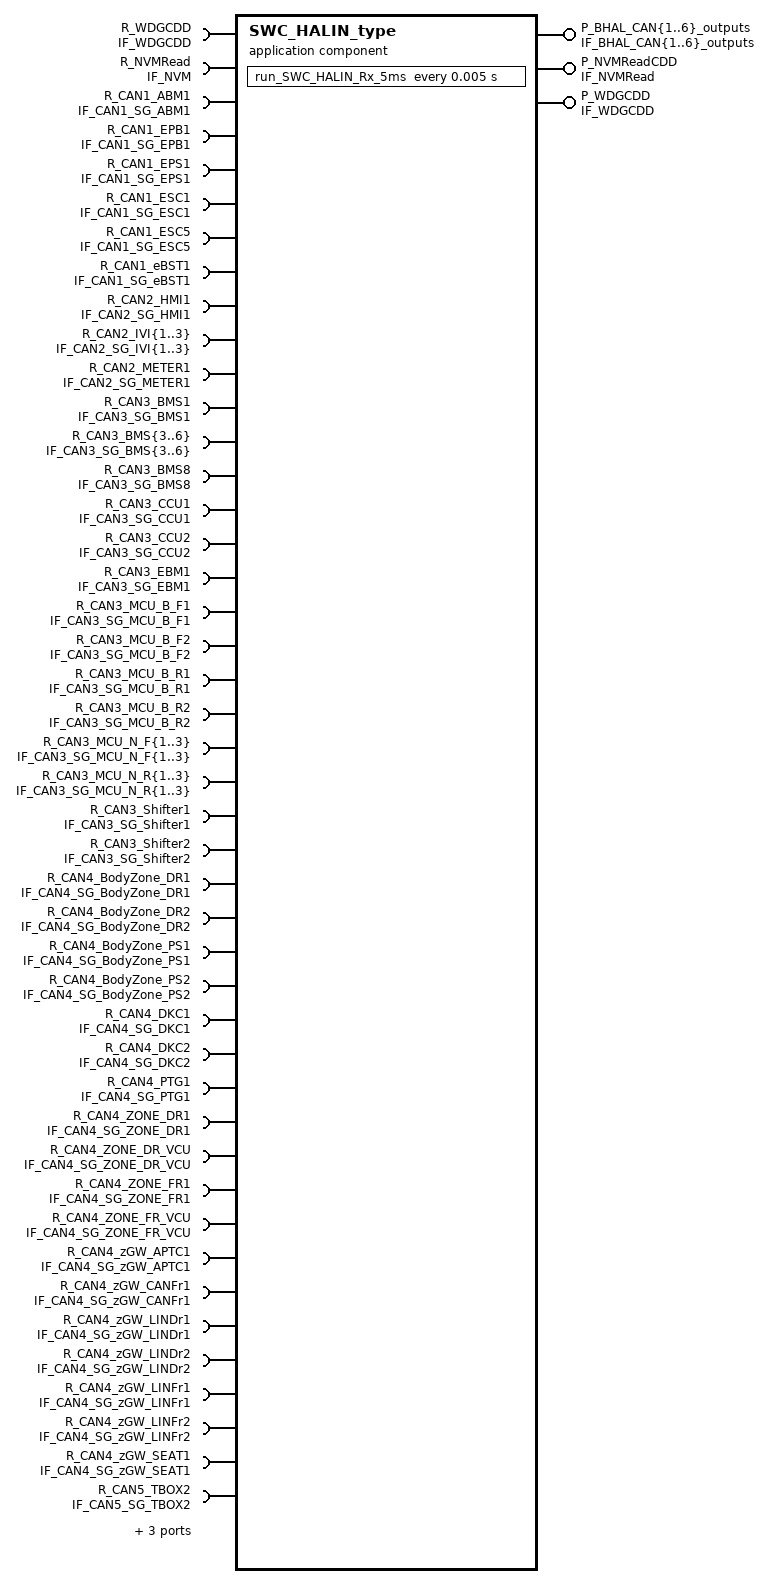
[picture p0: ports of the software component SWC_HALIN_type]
  application sw component type SWC_HALIN_type
    8 x provide port:
      P_BHAL_CAN{1..6}_outputs: provided-interface=IF_BHAL_CAN{1..6}_outputs
      P_NVMReadCDD: provided-interface=IF_NVMRead
      P_WDGCDD: provided-interface=IF_WDGCDD
    59 x require port:
      R_WDGCDD: required-interface=IF_WDGCDD
      R_NVMRead: nv-require-com-spec{init-value=1024 x 0, variable=NV_FVTDataArray}, required-interface=IF_NVM
      R_CAN1_ABM1: required-interface=IF_CAN1_SG_ABM1
      R_CAN1_EPB1: required-interface=IF_CAN1_SG_EPB1
      R_CAN1_EPS1: required-interface=IF_CAN1_SG_EPS1
      R_CAN1_ESC1: required-interface=IF_CAN1_SG_ESC1
      R_CAN1_ESC5: required-interface=IF_CAN1_SG_ESC5
      R_CAN1_eBST1: required-interface=IF_CAN1_SG_eBST1
      R_CAN2_HMI1: required-interface=IF_CAN2_SG_HMI1
      R_CAN2_IVI{1..3}: required-interface=IF_CAN2_SG_IVI{1..3}
      R_CAN2_METER1: required-interface=IF_CAN2_SG_METER1
      R_CAN3_BMS1: required-interface=IF_CAN3_SG_BMS1
      R_CAN3_BMS{3..6}: required-interface=IF_CAN3_SG_BMS{3..6}
      R_CAN3_BMS8: required-interface=IF_CAN3_SG_BMS8
      R_CAN3_CCU1: required-interface=IF_CAN3_SG_CCU1
      R_CAN3_CCU2: required-interface=IF_CAN3_SG_CCU2
      R_CAN3_EBM1: required-interface=IF_CAN3_SG_EBM1
      R_CAN3_MCU_B_F1: required-interface=IF_CAN3_SG_MCU_B_F1
      R_CAN3_MCU_B_F2: required-interface=IF_CAN3_SG_MCU_B_F2
      R_CAN3_MCU_B_R1: required-interface=IF_CAN3_SG_MCU_B_R1
      R_CAN3_MCU_B_R2: required-interface=IF_CAN3_SG_MCU_B_R2
      R_CAN3_MCU_N_F{1..3}: required-interface=IF_CAN3_SG_MCU_N_F{1..3}
      R_CAN3_MCU_N_R{1..3}: required-interface=IF_CAN3_SG_MCU_N_R{1..3}
      R_CAN3_Shifter1: required-interface=IF_CAN3_SG_Shifter1
      R_CAN3_Shifter2: required-interface=IF_CAN3_SG_Shifter2
      R_CAN4_BodyZone_DR1: required-interface=IF_CAN4_SG_BodyZone_DR1
      R_CAN4_BodyZone_DR2: required-interface=IF_CAN4_SG_BodyZone_DR2
      R_CAN4_BodyZone_PS1: required-interface=IF_CAN4_SG_BodyZone_PS1
      R_CAN4_BodyZone_PS2: required-interface=IF_CAN4_SG_BodyZone_PS2
      R_CAN4_DKC1: required-interface=IF_CAN4_SG_DKC1
      R_CAN4_DKC2: required-interface=IF_CAN4_SG_DKC2
      R_CAN4_PTG1: required-interface=IF_CAN4_SG_PTG1
      R_CAN4_ZONE_DR1: required-interface=IF_CAN4_SG_ZONE_DR1
      R_CAN4_ZONE_DR_VCU: required-interface=IF_CAN4_SG_ZONE_DR_VCU
      R_CAN4_ZONE_FR1: required-interface=IF_CAN4_SG_ZONE_FR1
      R_CAN4_ZONE_FR_VCU: required-interface=IF_CAN4_SG_ZONE_FR_VCU
      R_CAN4_zGW_APTC1: required-interface=IF_CAN4_SG_zGW_APTC1
      R_CAN4_zGW_CANFr1: required-interface=IF_CAN4_SG_zGW_CANFr1
      R_CAN4_zGW_LINDr1: required-interface=IF_CAN4_SG_zGW_LINDr1
      R_CAN4_zGW_LINDr2: required-interface=IF_CAN4_SG_zGW_LINDr2
      R_CAN4_zGW_LINFr1: required-interface=IF_CAN4_SG_zGW_LINFr1
      R_CAN4_zGW_LINFr2: required-interface=IF_CAN4_SG_zGW_LINFr2
      R_CAN4_zGW_SEAT1: required-interface=IF_CAN4_SG_zGW_SEAT1
      R_CAN5_TBOX2: required-interface=IF_CAN5_SG_TBOX2
      R_CAN5_TBOX3: required-interface=IF_CAN5_SG_TBOX3
      R_CAN6_FCM{1..4}: required-interface=IF_CAN6_SG_FCM{1..4}
      R_CAN6_SRR1: required-interface=IF_CAN6_SG_SRR1
    behavior SWC_HALIN_type_IB: handle-termination-and-restart=NO-SUPPORT, port-api-option{enable-take-address=false, indirect-api=false, port=P_WDGCDD}
      timing event TE_HALIN_5ms: start-on-event=run_SWC_HALIN_Rx_5ms, period=0.005
      operation invoked event oie_P_WDGCDD_CSOP_Call_WDG_AppStart: start-on-event=run_SWC_HALIN_AppCallWDG_StartUp, operation=P_WDGCDD.CSOP_Call_WDG_AppStart
      operation invoked event oie_P_WDGCDD_CSOP_Call_Watchdog: start-on-event=run_SWC_HALIN_AppCallWDG, operation=P_WDGCDD.CSOP_Call_Watchdog
      init event InitEvent_HALIN: start-on-event=run_SWC_HALIN_INIT
      4 x runnable:
        run_SWC_HALIN_Rx_5ms
          data-receive-point-by-arguments:
            57 x access:
              drparg_CAN1_SG_ABM1: accessed-variable=R_CAN1_ABM1.CAN1_SG_ABM1
              drparg_CAN1_SG_EPB1: accessed-variable=R_CAN1_EPB1.CAN1_SG_EPB1
              drparg_CAN1_SG_EPS1: accessed-variable=R_CAN1_EPS1.CAN1_SG_EPS1
              drparg_CAN1_SG_ESC1: accessed-variable=R_CAN1_ESC1.CAN1_SG_ESC1
              drparg_CAN1_SG_ESC5: accessed-variable=R_CAN1_ESC5.CAN1_SG_ESC5
              drparg_CAN1_SG_eBST1: accessed-variable=R_CAN1_eBST1.CAN1_SG_eBST1
              drparg_CAN2_SG_HMI1: accessed-variable=R_CAN2_HMI1.CAN2_SG_HMI1
              drparg_CAN2_SG_IVI{1..3}: accessed-variable=R_CAN2_IVI{1..3}.CAN2_SG_IVI{1..3}
              drparg_CAN2_SG_METER1: accessed-variable=R_CAN2_METER1.CAN2_SG_METER1
              drparg_CAN3_SG_BMS1: accessed-variable=R_CAN3_BMS1.CAN3_SG_BMS1
              drparg_CAN3_SG_BMS{3..6}: accessed-variable=R_CAN3_BMS{3..6}.CAN3_SG_BMS{3..6}
              drparg_CAN3_SG_BMS8: accessed-variable=R_CAN3_BMS8.CAN3_SG_BMS8
              drparg_CAN3_SG_CCU1: accessed-variable=R_CAN3_CCU1.CAN3_SG_CCU1
              drparg_CAN3_SG_CCU2: accessed-variable=R_CAN3_CCU2.CAN3_SG_CCU2
              drparg_CAN3_SG_EBM1: accessed-variable=R_CAN3_EBM1.CAN3_SG_EBM1
              drparg_CAN3_SG_MCU_B_F1: accessed-variable=R_CAN3_MCU_B_F1.CAN3_SG_MCU_B_F1
              drparg_CAN3_SG_MCU_B_F2: accessed-variable=R_CAN3_MCU_B_F2.CAN3_SG_MCU_B_F2
              drparg_CAN3_SG_MCU_B_R1: accessed-variable=R_CAN3_MCU_B_R1.CAN3_SG_MCU_B_R1
              drparg_CAN3_SG_MCU_B_R2: accessed-variable=R_CAN3_MCU_B_R2.CAN3_SG_MCU_B_R2
              drparg_CAN3_SG_MCU_N_F{1..3}: accessed-variable=R_CAN3_MCU_N_F{1..3}.CAN3_SG_MCU_N_F{1..3}
              drparg_CAN3_SG_MCU_N_R{1..3}: accessed-variable=R_CAN3_MCU_N_R{1..3}.CAN3_SG_MCU_N_R{1..3}
              drparg_CAN3_SG_Shifter1: accessed-variable=R_CAN3_Shifter1.CAN3_SG_Shifter1
              drparg_CAN3_SG_Shifter2: accessed-variable=R_CAN3_Shifter2.CAN3_SG_Shifter2
              drparg_CAN4_SG_BodyZone_DR1: accessed-variable=R_CAN4_BodyZone_DR1.CAN4_SG_BodyZone_DR1
              drparg_CAN4_SG_BodyZone_DR2: accessed-variable=R_CAN4_BodyZone_DR2.CAN4_SG_BodyZone_DR2
              drparg_CAN4_SG_BodyZone_PS1: accessed-variable=R_CAN4_BodyZone_PS1.CAN4_SG_BodyZone_PS1
              drparg_CAN4_SG_BodyZone_PS2: accessed-variable=R_CAN4_BodyZone_PS2.CAN4_SG_BodyZone_PS2
              drparg_CAN4_SG_DKC1: accessed-variable=R_CAN4_DKC1.CAN4_SG_DKC1
              drparg_CAN4_SG_DKC2: accessed-variable=R_CAN4_DKC2.CAN4_SG_DKC2
              drparg_CAN4_SG_PTG1: accessed-variable=R_CAN4_PTG1.CAN4_SG_PTG1
              drparg_CAN4_SG_ZONE_DR1: accessed-variable=R_CAN4_ZONE_DR1.CAN4_SG_ZONE_DR1
              drparg_CAN4_SG_ZONE_DR_VCU: accessed-variable=R_CAN4_ZONE_DR_VCU.CAN4_SG_ZONE_DR_VCU
              drparg_CAN4_SG_ZONE_FR1: accessed-variable=R_CAN4_ZONE_FR1.CAN4_SG_ZONE_FR1
              drparg_CAN4_SG_ZONE_FR_VCU: accessed-variable=R_CAN4_ZONE_FR_VCU.CAN4_SG_ZONE_FR_VCU
              drparg_CAN4_SG_zGW_APTC1: accessed-variable=R_CAN4_zGW_APTC1.CAN4_SG_zGW_APTC1
              drparg_CAN4_SG_zGW_CANFr1: accessed-variable=R_CAN4_zGW_CANFr1.CAN4_SG_zGW_CANFr1
              drparg_CAN4_SG_zGW_LINDr1: accessed-variable=R_CAN4_zGW_LINDr1.CAN4_SG_zGW_LINDr1
              drparg_CAN4_SG_zGW_LINDr2: accessed-variable=R_CAN4_zGW_LINDr2.CAN4_SG_zGW_LINDr2
              drparg_CAN4_SG_zGW_LINFr1: accessed-variable=R_CAN4_zGW_LINFr1.CAN4_SG_zGW_LINFr1
              drparg_CAN4_SG_zGW_LINFr2: accessed-variable=R_CAN4_zGW_LINFr2.CAN4_SG_zGW_LINFr2
              drparg_CAN4_SG_zGW_SEAT1: accessed-variable=R_CAN4_zGW_SEAT1.CAN4_SG_zGW_SEAT1
              drparg_CAN5_SG_TBOX2: accessed-variable=R_CAN5_TBOX2.CAN5_SG_TBOX2
              drparg_CAN5_SG_TBOX3: accessed-variable=R_CAN5_TBOX3.CAN5_SG_TBOX3
              drparg_CAN6_SG_FCM{1..4}: accessed-variable=R_CAN6_FCM{1..4}.CAN6_SG_FCM{1..4}
              drparg_CAN6_SG_SRR1: accessed-variable=R_CAN6_SRR1.CAN6_SG_SRR1
          data-send-points:
            6 x access:
              dsp_BHAL_CAN{1..6}_outputs: accessed-variable=P_BHAL_CAN{1..6}_outputs.BHAL_CAN{1..6}_outputs
          sync call scp_CSOP_Call_Watchdog: operation=R_WDGCDD.CSOP_Call_Watchdog, timeout=0.0
        run_SWC_HALIN_AppCallWDG
        run_SWC_HALIN_AppCallWDG_StartUp
        run_SWC_HALIN_INIT
          data-receive-point-by-arguments:
            access drparg_NV_FVTDataArray: accessed-variable=R_NVMRead.NV_FVTDataArray
          data-send-points:
            access dsp_u8_FVTNVMArray1024_type: accessed-variable=P_NVMReadCDD.u8Array1024_NVMReadData
          sync call scp_CSOP_Call_WDG_AppStart: operation=R_WDGCDD.CSOP_Call_WDG_AppStart, timeout=0.0
